# STM32F407 register map
File version: 1.2
CPU: CM4 r1p0, little endian, no MPU, no FPU, 4 interrupt priority bits
Registers are 32-bit, read-write, reset 0x0 unless marked. A register's access mark holds for its fields unless they carry their own. Offsets are from the block's base; [hi:lo] are bit positions; {n}, {i} and the like mark numbered series.

## SYSCFG — System configuration controller
Base 0x40013800
0x00 MEMRM — memory remap register
  [1:0] MEM_MODE
0x04 PMC — peripheral mode configuration register
  [23] MII_RMII_SEL — Ethernet PHY interface selection
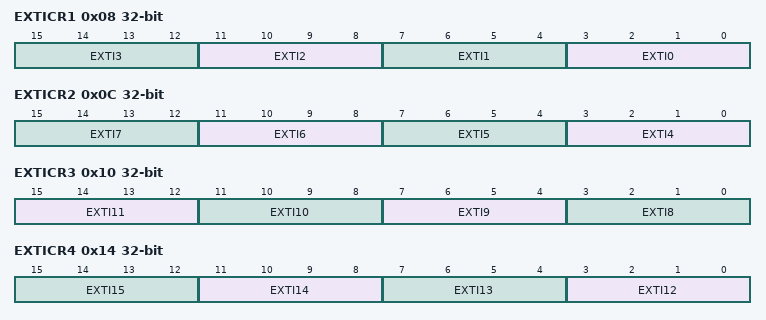
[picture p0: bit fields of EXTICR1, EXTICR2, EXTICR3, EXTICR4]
0x08 EXTICR1 — external interrupt configuration register 1
  [4n+3:4n] EXTI{n} (n=0..3) — EXTI x configuration (x = 0 to 3)
0x0C EXTICR2 — external interrupt configuration register 2
  [4n-13:4n-16] EXTI{n} (n=4..7) — EXTI x configuration (x = 4 to 7)
0x10 EXTICR3 — external interrupt configuration register 3
  [15:12] EXTI11 — EXTI x configuration (x = 8 to 11)
  [11:8] EXTI10
  [7:4] EXTI9 — EXTI x configuration (x = 8 to 11)
  [3:0] EXTI8 — EXTI x configuration (x = 8 to 11)
0x14 EXTICR4 — external interrupt configuration register 4
  [4n-45:4n-48] EXTI{n} (n=12..15) — EXTI x configuration (x = 12 to 15)
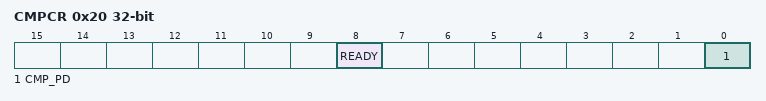
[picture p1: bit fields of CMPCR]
0x20 CMPCR ro — Compensation cell control register
  [8] READY
  [0] CMP_PD — Compensation cell power-down

## PWR — Power control
Base 0x40007000
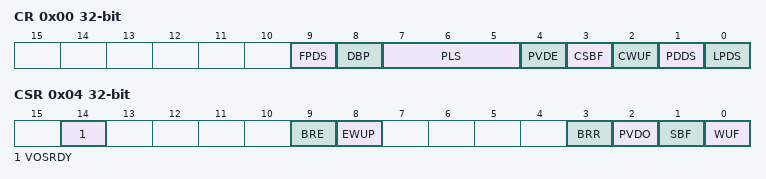
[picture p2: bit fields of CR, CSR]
0x00 CR — power control register
  [9] FPDS — Flash power down in Stop mode
  [8] DBP — Disable backup domain write protection
  [7:5] PLS — PVD level selection
  [4] PVDE — Power voltage detector enable
  [3] CSBF — Clear standby flag
  [2] CWUF — Clear wakeup flag
  [1] PDDS — Power down deepsleep
  [0] LPDS — Low-power deep sleep
0x04 CSR access per field — power control/status register
  [14] VOSRDY rw — Regulator voltage scaling output selection ready bit
  [9] BRE rw — Backup regulator enable
  [8] EWUP rw — Enable WKUP pin
  [3] BRR ro — Backup regulator ready
  [2] PVDO ro — PVD output
  [1] SBF ro — Standby flag
  [0] WUF ro — Wakeup flag

## IWDG — Independent watchdog
Base 0x40003000
0x00 KR wo — Key register
  [15:0] KEY — Key value (write only, read 0000h)
    0x5555=Enable access to PR, RLR and WINR registers (0x5555); 0xAAAA=Reset the watchdog value (0xAAAA); 0xCCCC=Start the watchdog (0xCCCC)
0x04 PR — Prescaler register
  [2:0] PR — Prescaler divider
    0=DivideBy4 (Divider /4); 1=DivideBy8 (Divider /8); 2=DivideBy16 (Divider /16); 3=DivideBy32 (Divider /32); 4=DivideBy64 (Divider /64); 5=DivideBy128 (Divider /128); 6=DivideBy256 (Divider /256); 7=DivideBy256bis (Divider /256)
0x08 RLR reset 0xFFF — Reload register
  [11:0] RL — Watchdog counter reload value
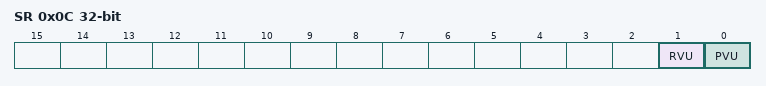
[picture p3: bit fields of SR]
0x0C SR ro — Status register
  [1] RVU — Watchdog counter reload value update
  [0] PVU — Watchdog prescaler value update

## WWDG — Window watchdog
Base 0x40002C00
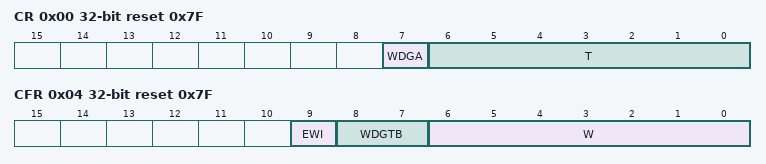
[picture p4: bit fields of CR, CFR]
0x00 CR reset 0x7F — Control register
  [7] WDGA — Activation bit
    0=Disabled (Watchdog disabled); 1=Enabled (Watchdog enabled)
  [6:0] T — 7-bit counter (MSB to LSB)
0x04 CFR reset 0x7F — Configuration register
  [9] EWI — Early wakeup interrupt
    on write: 1=Enable (interrupt occurs whenever the counter reaches the value 0x40)
  [8:7] WDGTB — Timer base
    0=Div1 (Counter clock (PCLK1 div 4096) div 1); 1=Div2 (Counter clock (PCLK1 div 4096) div 2); 2=Div4 (Counter clock (PCLK1 div 4096) div 4); 3=Div8 (Counter clock (PCLK1 div 4096) div 8)
  [6:0] W — 7-bit window value
0x08 SR — Status register
  [0] EWIF — Early wakeup interrupt flag
    on read: 1=Pending (The EWI Interrupt Service Routine has been triggered); 0=Finished (The EWI Interrupt Service Routine has been serviced) | on write: 0=Finished (The EWI Interrupt Service Routine has been serviced)

## TIM10 — General-purpose-timers
Base 0x40014400
Same registers: TIM13 0x40001C00, TIM14 0x40002000
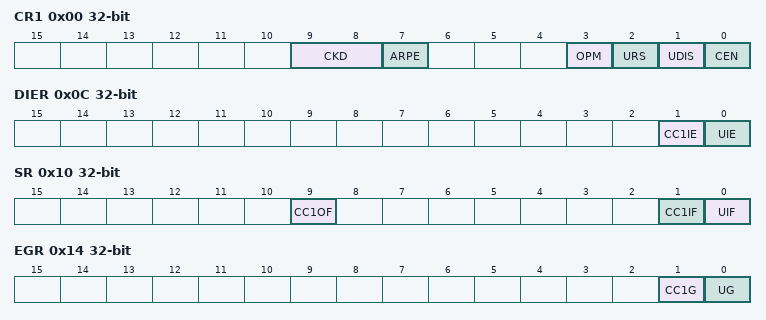
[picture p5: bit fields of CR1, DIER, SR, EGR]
0x00 CR1 — control register 1
  [9:8] CKD — Clock division
    0=Div1 (t_DTS = t_CK_INT); 1=Div2 (t_DTS = 2 × t_CK_INT); 2=Div4 (t_DTS = 4 × t_CK_INT)
  [7] ARPE — Auto-reload preload enable
    0=Disabled (TIMx_APRR register is not buffered); 1=Enabled (TIMx_APRR register is buffered)
  [3] OPM — One-pulse mode
    0=Disabled (Counter is not stopped at update event); 1=Enabled (Counter stops counting at the next update event (clearing the CEN bit))
  [2] URS — Update request source
    0=AnyEvent (Any of counter overflow/underflow, setting UG, or update through slave mode, generates an update interrupt or DMA request); 1=CounterOnly (Only counter overflow/underflow generates an update interrupt or DMA request)
  [1] UDIS — Update disable
    0=Enabled (Update event enabled); 1=Disabled (Update event disabled)
  [0] CEN — Counter enable
    0=Disabled (Counter disabled); 1=Enabled (Counter enabled)
0x0C DIER — DMA/Interrupt enable register
  [1] CC1IE — Capture/Compare 1 interrupt enable
  [0] UIE — Update interrupt enable
    0=Disabled (Update interrupt disabled); 1=Enabled (Update interrupt enabled)
0x10 SR — status register
  [9] CC1OF — Capture/Compare 1 overcapture flag
  [1] CC1IF — Capture/compare 1 interrupt flag
  [0] UIF — Update interrupt flag
    0=Clear (No update occurred); 1=UpdatePending (Update interrupt pending.)
0x14 EGR wo — event generation register
  [1] CC1G — Capture/compare 1 generation
  [0] UG — Update generation
    1=Update (Re-initializes the timer counter and generates an update of the registers.)
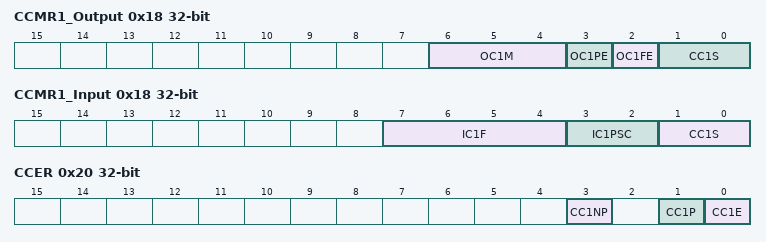
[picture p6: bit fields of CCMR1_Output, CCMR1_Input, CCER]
0x18 CCMR1_Output — capture/compare mode register 1 (output mode)
  [6:4] OC1M — Output Compare 1 mode
    0=Frozen (The comparison between the output compare register TIMx_CCRy and the counter TIMx_CNT has no effect on the outputs); 1=ActiveOnMatch (Set channel to active level on match. OCyREF signal is forced high when the counter matches the capture/compare register); 2=InactiveOnMatch (Set channel to inactive level on match. OCyREF signal is forced low when the counter matches the capture/compare register); 3=Toggle (OCyREF toggles when TIMx_CNT=TIMx_CCRy); 4=ForceInactive (OCyREF is forced low); 5=ForceActive (OCyREF is forced high); 6=PwmMode1 (In upcounting, channel is active as long as TIMx_CNT<TIMx_CCRy else inactive. In downcounting, channel is inactive as long as TIMx_CNT>TIMx_CCRy else active); 7=PwmMode2 (Inversely to PwmMode1)
  [3] OC1PE — Output Compare 1 preload enable
  [2] OC1FE — Output Compare 1 fast enable
  [1:0] CC1S — Capture/Compare 1 selection
0x18 CCMR1_Input (alternate view of CCMR1_Output) — capture/compare mode register 1 (input mode)
  [7:4] IC1F — Input capture 1 filter
  [3:2] IC1PSC — Input capture 1 prescaler
  [1:0] CC1S — Capture/Compare 1 selection
0x20 CCER — capture/compare enable register
  [3] CC1NP — Capture/Compare 1 output Polarity
  [1] CC1P — Capture/Compare 1 output Polarity
  [0] CC1E — Capture/Compare 1 output enable
0x24 CNT — counter
  [15:0] CNT — counter value
0x28 PSC — prescaler
  [15:0] PSC — Prescaler value
0x2C ARR — auto-reload register
  [15:0] ARR — Auto-reload value
0x34 CCR{i} (i=1..1; step 0x0) — capture/compare register
  [15:0] CCR — Capture/Compare value

## TIM11 — General-purpose-timers
Base 0x40014800
Registers as TIM10; these are added or differ:
0x50 OR — option register
  [1:0] RMP — Input 1 remapping capability
